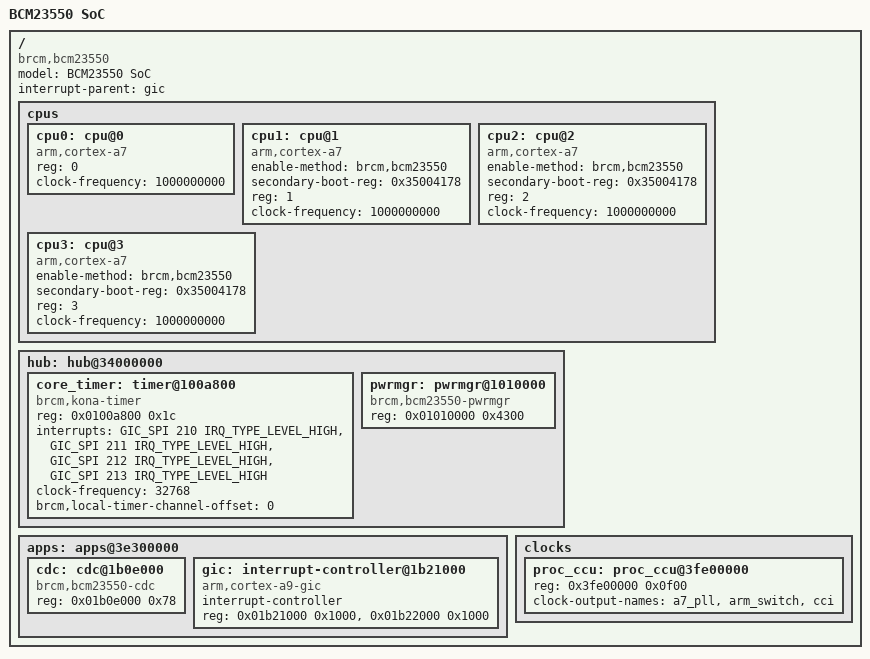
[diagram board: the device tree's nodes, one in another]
/*
 *  BSD LICENSE
 *
 *  Copyright(c) 2016 Broadcom.  All rights reserved.
 *
 *  Redistribution and use in source and binary forms, with or without
 *  modification, are permitted provided that the following conditions
 *  are met:
 *
 *    * Redistributions of source code must retain the above copyright
 *      notice, this list of conditions and the following disclaimer.
 *    * Redistributions in binary form must reproduce the above copyright
 *      notice, this list of conditions and the following disclaimer in
 *      the documentation and/or other materials provided with the
 *      distribution.
 *    * Neither the name of Broadcom Corporation nor the names of its
 *      contributors may be used to endorse or promote products derived
 *      from this software without specific prior written permission.
 *
 *  THIS SOFTWARE IS PROVIDED BY THE COPYRIGHT HOLDERS AND CONTRIBUTORS
 *  "AS IS" AND ANY EXPRESS OR IMPLIED WARRANTIES, INCLUDING, BUT NOT
 *  LIMITED TO, THE IMPLIED WARRANTIES OF MERCHANTABILITY AND FITNESS FOR
 *  A PARTICULAR PURPOSE ARE DISCLAIMED. IN NO EVENT SHALL THE COPYRIGHT
 *  OWNER OR CONTRIBUTORS BE LIABLE FOR ANY DIRECT, INDIRECT, INCIDENTAL,
 *  SPECIAL, EXEMPLARY, OR CONSEQUENTIAL DAMAGES (INCLUDING, BUT NOT
 *  LIMITED TO, PROCUREMENT OF SUBSTITUTE GOODS OR SERVICES; LOSS OF USE,
 *  DATA, OR PROFITS; OR BUSINESS INTERRUPTION) HOWEVER CAUSED AND ON ANY
 *  THEORY OF LIABILITY, WHETHER IN CONTRACT, STRICT LIABILITY, OR TORT
 *  (INCLUDING NEGLIGENCE OR OTHERWISE) ARISING IN ANY WAY OUT OF THE USE
 * OF THIS SOFTWARE, EVEN IF ADVISED OF THE POSSIBILITY OF SUCH DAMAGE.
 */

#include "bcm21664-common.dtsi"

#include <dt-bindings/interrupt-controller/arm-gic.h>

/ {
	#address-cells = <1>;
	#size-cells = <1>;
	model = "BCM23550 SoC";
	compatible = "brcm,bcm23550";
	interrupt-parent = <&gic>;

	cpus {
		#address-cells = <1>;
		#size-cells = <0>;

		cpu0: cpu@0 {
			device_type = "cpu";
			compatible = "arm,cortex-a7";
			reg = <0>;
			clock-frequency = <1000000000>;
		};

		cpu1: cpu@1 {
			device_type = "cpu";
			compatible = "arm,cortex-a7";
			enable-method = "brcm,bcm23550";
			secondary-boot-reg = <0x35004178>;
			reg = <1>;
			clock-frequency = <1000000000>;
		};

		cpu2: cpu@2 {
			device_type = "cpu";
			compatible = "arm,cortex-a7";
			enable-method = "brcm,bcm23550";
			secondary-boot-reg = <0x35004178>;
			reg = <2>;
			clock-frequency = <1000000000>;
		};

		cpu3: cpu@3 {
			device_type = "cpu";
			compatible = "arm,cortex-a7";
			enable-method = "brcm,bcm23550";
			secondary-boot-reg = <0x35004178>;
			reg = <3>;
			clock-frequency = <1000000000>;
		};
	};

	hub: hub@34000000 {
		core_timer: timer@100a800 {
			compatible = "brcm,kona-timer";
			reg = <0x0100a800 0x1c>;
			interrupts = <GIC_SPI 210 IRQ_TYPE_LEVEL_HIGH>,
				<GIC_SPI 211 IRQ_TYPE_LEVEL_HIGH>,
				<GIC_SPI 212 IRQ_TYPE_LEVEL_HIGH>,
				<GIC_SPI 213 IRQ_TYPE_LEVEL_HIGH>;
			clock-frequency = <32768>; /* static 32khz */
			brcm,local-timer-channel-offset = <0>;
		};

		pwrmgr: pwrmgr@1010000 {
			compatible = "brcm,bcm23550-pwrmgr";
			reg = <0x01010000 0x4300>;
			#power-domain-cells = <1>;
		};
	};

	apps: apps@3e300000 {
		cdc: cdc@1b0e000 {
			compatible = "brcm,bcm23550-cdc";
			reg = <0x01b0e000 0x78>;
		};

		gic: interrupt-controller@1b21000 {
			compatible = "arm,cortex-a9-gic";
			#interrupt-cells = <3>;
			#address-cells = <0>;
			interrupt-controller;
			reg = <0x01b21000 0x1000>,
			      <0x01b22000 0x1000>;
		};
	};

	clocks {
		proc_ccu: proc_ccu@3fe00000 {
			compatible = BCM23550_DT_PROC_CCU_COMPAT;
			reg = <0x3fe00000 0x0f00>;
			#clock-cells = <1>;
			clock-output-names = "a7_pll",
					     "arm_switch",
					     "cci";
		};
	};
};
